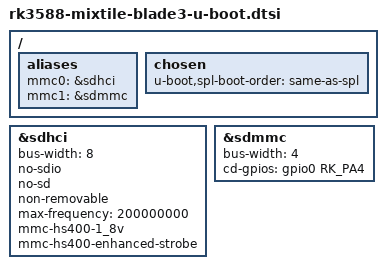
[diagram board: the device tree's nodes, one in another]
// SPDX-License-Identifier: (GPL-2.0+ OR MIT)
/*
 * Copyright (c) 2022 Mixtile Limited
 *
 */

#include <dt-bindings/gpio/gpio.h>
#include <dt-bindings/pinctrl/rockchip.h>
#include "rk3588-u-boot.dtsi"

/ {
	aliases {
		mmc0 = &sdhci;
		mmc1 = &sdmmc;
	};

	chosen {
		u-boot,spl-boot-order = "same-as-spl", &sdmmc, &sdhci;
	};

};

// These must be defined early for the SPL
&sdhci {
	bus-width = <8>;
	no-sdio;
	no-sd;
	non-removable;
	max-frequency = <200000000>;
	mmc-hs400-1_8v;
	mmc-hs400-enhanced-strobe;
	status = "okay";
};

// For some reason if this is not defined here then UART input will not work
&sdmmc {
	bus-width = <4>;
	cd-gpios = <&gpio0 RK_PA4 GPIO_ACTIVE_HIGH>;
	status = "okay";
};
